# GD32E25x register map
File version: 1.0
CPU: CM23 r1p0, little endian, no MPU, no FPU, 2 interrupt priority bits
Registers are 32-bit, read-write, reset 0x0 unless marked. A register's access mark holds for its fields unless they carry their own. Offsets are from the block's base; [hi:lo] are bit positions; {n}, {i} and the like mark numbered series.

## FMC
Base 0x40022000
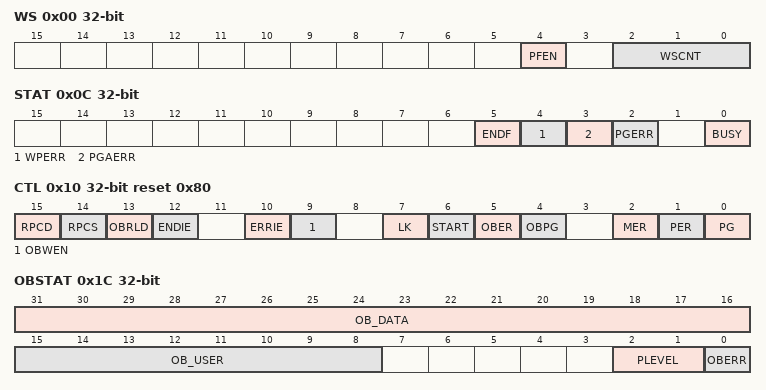
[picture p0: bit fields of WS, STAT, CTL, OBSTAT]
0x00 WS — wait state register
  [4] PFEN — Pre-fetch enable
  [2:0] WSCNT — wait state counter register
0x04 KEY wo — Unlock key register
  [31:0] KEY — FMC_CTL unlock register
0x08 OBKEY wo — Option byte unlock key register
  [31:0] OBKEY — FMC_ CTL option bytes operation unlock register
0x0C STAT access per field — Status register
  [5] ENDF rw — End of operation flag bit
  [4] WPERR rw — Erase/Program protection error flag bit
  [3] PGAERR rw — Program alignment error flag bit
  [2] PGERR rw — Program error flag bit
  [0] BUSY ro — The flash is busy bit
0x10 CTL reset 0x80 — Control register
  [15] RPCD — RAM parity check disable
  [14] RPCS — RAM parity check control selection
  [13] OBRLD — Option byte reload bit
  [12] ENDIE — End of operation interrupt enable bit
  [10] ERRIE — Error interrupt enable bit
  [9] OBWEN — Option byte erase/program enable bit
  [7] LK — FMC_CTL lock bit
  [6] START — Send erase command to FMC bit
  [5] OBER — Option bytes erase command bit
  [4] OBPG — Option bytes program command bit
  [2] MER — Main flash mass erase for bank0 command bit
  [1] PER — Main flash page erase for bank0 command bit
  [0] PG — Main flash program for bank0 command bit
0x14 ADDR — Address register
  [31:0] ADDR — Flash erase/program command address bits
0x1C OBSTAT ro — Option byte status register
  [31:16] OB_DATA — Store DATA[15:0] of option bytes block after system reset
  [15:8] OB_USER — Store USER of option bytes block after system reset
  [2:1] PLEVEL — Option bytes security protection level
  [0] OBERR — Option bytes read error bit
0x20 WP ro — Erase/Program Protection register
  [15:0] OB_WP — Store WP[15:0] of option bytes block after system reset
0x100 PID ro — Product ID register
  [31:0] PID — Product reserved ID code register

## FWDGT — free watchdog timer
Base 0x40003000
0x00 CTL wo — Control register
  [15:0] CMD — Key value
0x04 PSC — Prescaler register
  [2:0] PSC — Prescaler divider
0x08 RLD reset 0xFFF — Reload register
  [11:0] RLD — Watchdog counter reload value
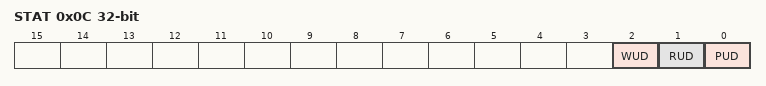
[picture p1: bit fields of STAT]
0x0C STAT ro — Status register
  [2] WUD — Watchdog counter window value update
  [1] RUD — Watchdog counter reload value update
  [0] PUD — Watchdog prescaler value update
0x10 WND reset 0xFFF — Window register
  [11:0] WND — Watchdog counter window value

## GPIOA — General-purpose I/Os
Base 0x48000000
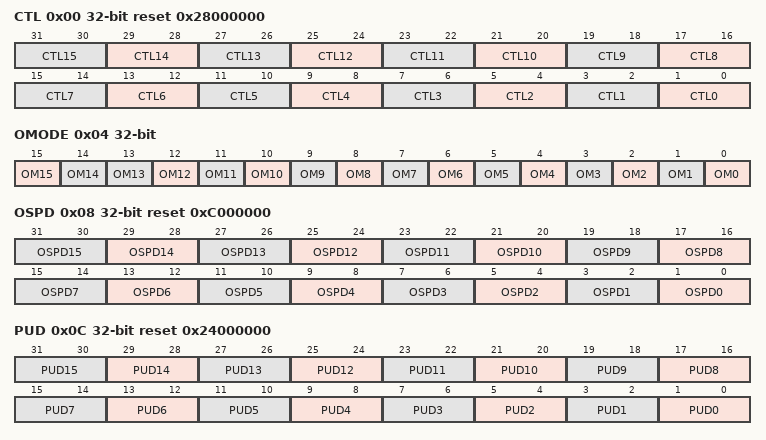
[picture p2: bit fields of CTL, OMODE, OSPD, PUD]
0x00 CTL reset 0x28000000 — GPIO port control register
  [2n+1:2n] CTL{n} (n=0..15) — Pin {n} configuration bits
0x04 OMODE — GPIO port output type register
  [15] OM15 — Pin 15 output mode bit
  [14] OM14 — Pin 15 output mode bit
  [n] OM{n} (n=0..13) — Pin {n} output mode bit
0x08 OSPD reset 0xC000000 — GPIO port output speed register
  [2n+1:2n] OSPD{n} (n=0..15) — Pin {n} output max speed bits
0x0C PUD reset 0x24000000 — GPIO port pull-up/pull-down register
  [2n+1:2n] PUD{n} (n=0..15) — Pin {n} pull-up or pull-down bits
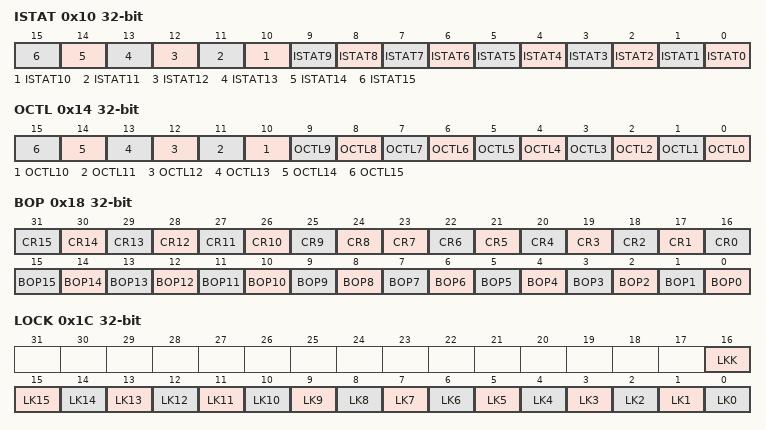
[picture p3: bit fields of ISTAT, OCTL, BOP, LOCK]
0x10 ISTAT ro — GPIO input status register
  [n] ISTAT{n} (n=0..15) — Port input status
0x14 OCTL — GPIO port output control register
  [n] OCTL{n} (n=0..15) — Port output data (y = 0..15)
0x18 BOP wo — GPIO port bit operate register
  [n+16] CR{n} (n=8..15) — Pin {n} reset bit
  [23] CR7 — Pin 7 reset bit)
  [n+16] CR{n} (n=2..6) — Pin {n} reset bit
  [17] CR1 — Pin 2 reset bit
  [16] CR0 — Pin 0 reset bit
  [n] BOP{n} (n=0..15) — Pin {n} set bit
0x1C LOCK — GPIO port configuration lock register
  [16] LKK — Lock key
  [n] LK{n} (n=0..15) — Port A lock bit {n}
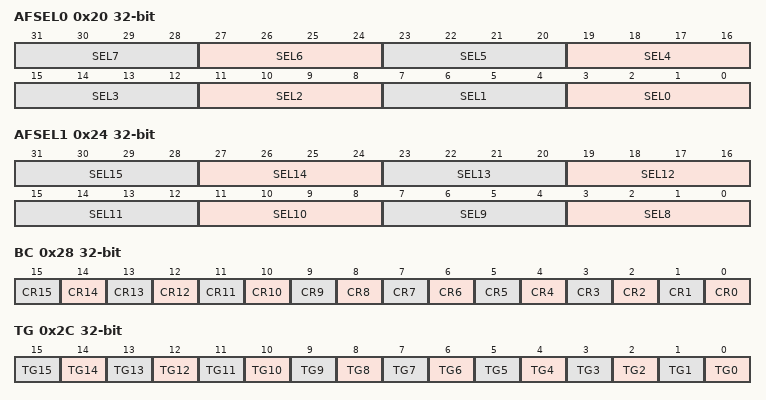
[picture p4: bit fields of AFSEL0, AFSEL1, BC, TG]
0x20 AFSEL0 — GPIO alternate function selected register 0
  [4n+3:4n] SEL{n} (n=0..7) — Pin {n} alternate function selected
0x24 AFSEL1 — GPIO alternate function seclected register 1
  [4n-29:4n-32] SEL{n} (n=8..15) — Pin {n} alternate function selected
0x28 BC wo — Port bit reset register
  [n] CR{n} (n=0..15) — Port cleat bit
0x2C TG wo — Port bit toggle register
  [n] TG{n} (n=0..15) — Port toggle bit
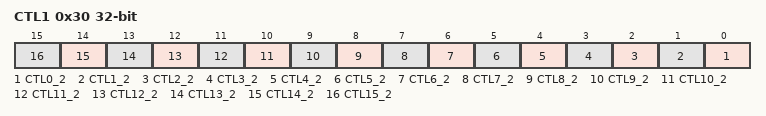
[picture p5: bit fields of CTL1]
0x30 CTL1 — GPIO port control register 1
  [n] CTL{n}_2 (n=0..15) — Pin {n} configuration bits
